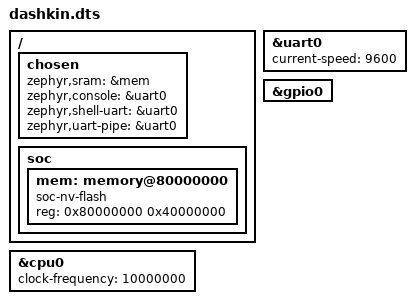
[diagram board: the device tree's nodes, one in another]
/dts-v1/;

#include <dashkin.dtsi>
#include <freq.h>
#include <mem.h>

/ {
	chosen {
		zephyr,sram = &mem;
		zephyr,console = &uart0;
		zephyr,shell-uart = &uart0;
		zephyr,uart-pipe = &uart0;
	};

	soc {
		mem: memory@80000000 {
			compatible = "soc-nv-flash", "mmio-sram";
      device_type = "memory";
			reg = <0x80000000 0x40000000>;
		};
	};
};

&cpu0 {
	clock-frequency = <10000000>;
};

&uart0 {
	status = "okay";
	current-speed = <9600>;
};

&gpio0 {
  status = "okay";
};
